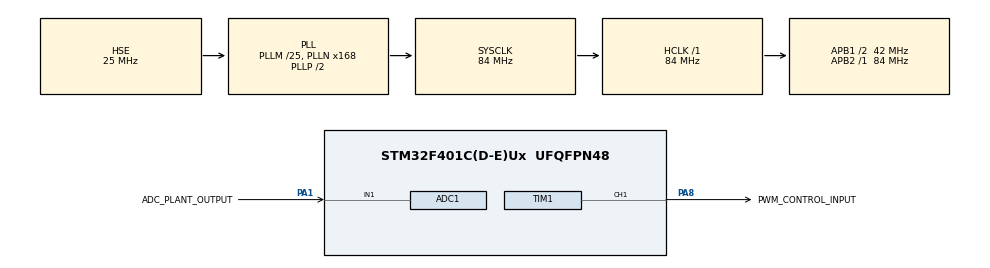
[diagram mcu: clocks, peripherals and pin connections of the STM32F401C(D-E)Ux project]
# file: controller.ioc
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ADC1.Channel-0\#ChannelRegularConversion=ADC_CHANNEL_1
ADC1.ClockPrescaler=ADC_CLOCK_SYNC_PCLK_DIV8
ADC1.ContinuousConvMode=ENABLE
ADC1.DMAContinuousRequests=ENABLE
ADC1.NbrOfConversionFlag=1
ADC1.Rank-0\#ChannelRegularConversion=1
ADC1.SamplingTime-0\#ChannelRegularConversion=ADC_SAMPLETIME_112CYCLES
ADC1.master=1
Dma.ADC1.0.Direction=DMA_PERIPH_TO_MEMORY
Dma.ADC1.0.FIFOMode=DMA_FIFOMODE_DISABLE
Dma.ADC1.0.Instance=DMA2_Stream0
Dma.ADC1.0.MemDataAlignment=DMA_MDATAALIGN_HALFWORD
Dma.ADC1.0.MemInc=DMA_MINC_ENABLE
Dma.ADC1.0.Mode=DMA_CIRCULAR
Dma.ADC1.0.PeriphDataAlignment=DMA_PDATAALIGN_HALFWORD
Dma.ADC1.0.PeriphInc=DMA_PINC_DISABLE
Dma.ADC1.0.Priority=DMA_PRIORITY_LOW
Dma.Request0=ADC1
Dma.Request1=TIM1_CH1
Dma.TIM1_CH1.1.Direction=DMA_PERIPH_TO_MEMORY
Dma.TIM1_CH1.1.FIFOMode=DMA_FIFOMODE_DISABLE
Dma.TIM1_CH1.1.Instance=DMA2_Stream1
Dma.TIM1_CH1.1.MemDataAlignment=DMA_MDATAALIGN_HALFWORD
Dma.TIM1_CH1.1.MemInc=DMA_MINC_ENABLE
Dma.TIM1_CH1.1.Mode=DMA_CIRCULAR
Dma.TIM1_CH1.1.PeriphDataAlignment=DMA_PDATAALIGN_HALFWORD
Dma.TIM1_CH1.1.PeriphInc=DMA_PINC_DISABLE
Dma.TIM1_CH1.1.Priority=DMA_PRIORITY_LOW
Mcu.Family=STM32F4
Mcu.Name=STM32F401C(D-E)Ux
Mcu.Package=UFQFPN48
Mcu.UserConstants=PWM_COUNTER_PERIOD,1000-1
NVIC.DMA2_Stream0_IRQn=true\:0\:0\:false\:false\:true\:false\:true\:true
NVIC.DMA2_Stream1_IRQn=true\:0\:0\:false\:false\:true\:false\:true\:true
NVIC.PriorityGroup=NVIC_PRIORITYGROUP_4
NVIC.TIM2_IRQn=true\:0\:0\:false\:false\:true\:true\:true\:true
PA1.GPIO_Label=ADC_PLANT_OUTPUT
PA1.Signal=ADCx_IN1
PA13.Mode=Serial_Wire
PA13.Signal=SYS_JTMS-SWDIO
PA14.Mode=Serial_Wire
PA14.Signal=SYS_JTCK-SWCLK
PA8.GPIO_Label=PWM_CONTROL_INPUT
PA8.Signal=S_TIM1_CH1
PH0\ -\ OSC_IN.Mode=HSE-External-Oscillator
PH0\ -\ OSC_IN.Signal=RCC_OSC_IN
PH1\ -\ OSC_OUT.Mode=HSE-External-Oscillator
PH1\ -\ OSC_OUT.Signal=RCC_OSC_OUT
ProjectManager.HeapSize=0x200
ProjectManager.StackSize=0x400
ProjectManager.TargetToolchain=STM32CubeIDE
RCC.48MHZClocksFreq_Value=42000000
RCC.AHBFreq_Value=84000000
RCC.APB1CLKDivider=RCC_HCLK_DIV2
RCC.APB1Freq_Value=42000000
RCC.APB1TimFreq_Value=84000000
RCC.APB2Freq_Value=84000000
RCC.APB2TimFreq_Value=84000000
RCC.CortexFreq_Value=84000000
RCC.HCLKFreq_Value=84000000
RCC.HSE_VALUE=25000000
RCC.HSI_VALUE=16000000
RCC.LSE_VALUE=32768
RCC.PLLM=25
RCC.PLLN=168
RCC.PLLSourceVirtual=RCC_PLLSOURCE_HSE
RCC.SYSCLKFreq_VALUE=84000000
RCC.SYSCLKSource=RCC_SYSCLKSOURCE_PLLCLK
RCC.VCOOutputFreq_Value=168000000
SH.ADCx_IN1.0=ADC1_IN1,IN1
SH.S_TIM1_CH1.0=TIM1_CH1,PWM Generation1 CH1
TIM1.Channel-PWM\ Generation1\ CH1=TIM_CHANNEL_1
TIM1.Period=PWM_COUNTER_PERIOD
TIM1.Prescaler=84-1
TIM2.Period=50000-1
TIM2.Prescaler=84-1
VP_TIM2_VS_ClockSourceINT.Mode=Internal
board=custom

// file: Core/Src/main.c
/* USER CODE BEGIN Header */
/**
  ******************************************************************************
  * @file           : main.c
  * @brief          : Main program body
  ******************************************************************************
  * @attention
  *
  * Copyright (c) 2025 STMicroelectronics.
  * All rights reserved.
  *
  * This software is licensed under terms that can be found in the LICENSE file
  * in the root directory of this software component.
  * If no LICENSE file comes with this software, it is provided AS-IS.
  *
  ******************************************************************************
  */
/* USER CODE END Header */
#include "main.h"

/* USER CODE BEGIN Includes */
#include "ControllerModel.h"
#include "ReferenceInputModel.h"
/* USER CODE END Includes */

/* USER CODE BEGIN PD */
#define VOLT_REF 3.33f
#define DATA12_TO_VOLT (VOLT_REF/0xfff)
#define VOLT_TO_PWM_DUTY ((PWM_COUNTER_PERIOD)/VOLT_REF)
/* USER CODE END PD */

ADC_HandleTypeDef hadc1;
DMA_HandleTypeDef hdma_adc1;

TIM_HandleTypeDef htim1;
TIM_HandleTypeDef htim2;
DMA_HandleTypeDef hdma_tim1_ch1;

/* USER CODE BEGIN PV */
uint16_t dma_adc_sensor_input = 0;
uint16_t dma_pwm_duty_out = 0;
uint16_t pwm_out_duty = 0;

float y = 0.f, r = 1.f, e = 0.f, u = 0.f;
/* USER CODE END PV */

void SystemClock_Config(void);
static void MX_GPIO_Init(void);
static void MX_DMA_Init(void);
static void MX_ADC1_Init(void);
static void MX_TIM1_Init(void);
static void MX_TIM2_Init(void);

int main(void)
{

  /* MCU Configuration--------------------------------------------------------*/

  /* Reset of all peripherals, Initializes the Flash interface and the Systick. */
  HAL_Init();

  /* Configure the system clock */
  SystemClock_Config();

  /* Initialize all configured peripherals */
  MX_GPIO_Init();
  MX_DMA_Init();
  MX_ADC1_Init();
  MX_TIM1_Init();
  MX_TIM2_Init();
  /* USER CODE BEGIN 2 */
  ControllerModel_initialize();
  ReferenceInputModel_initialize();
  HAL_TIM_PWM_Start_DMA(&htim1, TIM_CHANNEL_1, (uint32_t*) &dma_pwm_duty_out, (uint32_t) 1);
  HAL_ADC_Start_DMA(&hadc1, (uint32_t*) &dma_adc_sensor_input, (uint32_t) 1);
  HAL_TIM_Base_Start_IT(&htim2);
  /* USER CODE END 2 */

  /* Infinite loop */
  while (1)
  {

  }
}

void SystemClock_Config(void)
{
  RCC_OscInitTypeDef RCC_OscInitStruct = {0};
  RCC_ClkInitTypeDef RCC_ClkInitStruct = {0};

  /** Configure the main internal regulator output voltage
  */
  __HAL_RCC_PWR_CLK_ENABLE();
  __HAL_PWR_VOLTAGESCALING_CONFIG(PWR_REGULATOR_VOLTAGE_SCALE2);

  /** Initializes the RCC Oscillators according to the specified parameters
  * in the RCC_OscInitTypeDef structure.
  */
  RCC_OscInitStruct.OscillatorType = RCC_OSCILLATORTYPE_HSE;
  RCC_OscInitStruct.HSEState = RCC_HSE_ON;
  RCC_OscInitStruct.PLL.PLLState = RCC_PLL_ON;
  RCC_OscInitStruct.PLL.PLLSource = RCC_PLLSOURCE_HSE;
  RCC_OscInitStruct.PLL.PLLM = 25;
  RCC_OscInitStruct.PLL.PLLN = 168;
  RCC_OscInitStruct.PLL.PLLP = RCC_PLLP_DIV2;
  RCC_OscInitStruct.PLL.PLLQ = 4;
  if (HAL_RCC_OscConfig(&RCC_OscInitStruct) != HAL_OK)
  {
    Error_Handler();
  }

  /** Initializes the CPU, AHB and APB buses clocks
  */
  RCC_ClkInitStruct.ClockType = RCC_CLOCKTYPE_HCLK|RCC_CLOCKTYPE_SYSCLK
                              |RCC_CLOCKTYPE_PCLK1|RCC_CLOCKTYPE_PCLK2;
  RCC_ClkInitStruct.SYSCLKSource = RCC_SYSCLKSOURCE_PLLCLK;
  RCC_ClkInitStruct.AHBCLKDivider = RCC_SYSCLK_DIV1;
  RCC_ClkInitStruct.APB1CLKDivider = RCC_HCLK_DIV2;
  RCC_ClkInitStruct.APB2CLKDivider = RCC_HCLK_DIV1;

  if (HAL_RCC_ClockConfig(&RCC_ClkInitStruct, FLASH_LATENCY_2) != HAL_OK)
  {
    Error_Handler();
  }
}

static void MX_ADC1_Init(void)
{

  ADC_ChannelConfTypeDef sConfig = {0};

  /** Configure the global features of the ADC (Clock, Resolution, Data Alignment and number of conversion)
  */
  hadc1.Instance = ADC1;
  hadc1.Init.ClockPrescaler = ADC_CLOCK_SYNC_PCLK_DIV8;
  hadc1.Init.Resolution = ADC_RESOLUTION_12B;
  hadc1.Init.ScanConvMode = DISABLE;
  hadc1.Init.ContinuousConvMode = ENABLE;
  hadc1.Init.DiscontinuousConvMode = DISABLE;
  hadc1.Init.ExternalTrigConvEdge = ADC_EXTERNALTRIGCONVEDGE_NONE;
  hadc1.Init.ExternalTrigConv = ADC_SOFTWARE_START;
  hadc1.Init.DataAlign = ADC_DATAALIGN_RIGHT;
  hadc1.Init.NbrOfConversion = 1;
  hadc1.Init.DMAContinuousRequests = ENABLE;
  hadc1.Init.EOCSelection = ADC_EOC_SINGLE_CONV;
  if (HAL_ADC_Init(&hadc1) != HAL_OK)
  {
    Error_Handler();
  }

  /** Configure for the selected ADC regular channel its corresponding rank in the sequencer and its sample time.
  */
  sConfig.Channel = ADC_CHANNEL_1;
  sConfig.Rank = 1;
  sConfig.SamplingTime = ADC_SAMPLETIME_112CYCLES;
  if (HAL_ADC_ConfigChannel(&hadc1, &sConfig) != HAL_OK)
  {
    Error_Handler();
  }

}

static void MX_TIM1_Init(void)
{

  TIM_MasterConfigTypeDef sMasterConfig = {0};
  TIM_OC_InitTypeDef sConfigOC = {0};
  TIM_BreakDeadTimeConfigTypeDef sBreakDeadTimeConfig = {0};

  htim1.Instance = TIM1;
  htim1.Init.Prescaler = 84-1;
  htim1.Init.CounterMode = TIM_COUNTERMODE_UP;
  htim1.Init.Period = PWM_COUNTER_PERIOD;
  htim1.Init.ClockDivision = TIM_CLOCKDIVISION_DIV1;
  htim1.Init.RepetitionCounter = 0;
  htim1.Init.AutoReloadPreload = TIM_AUTORELOAD_PRELOAD_DISABLE;
  if (HAL_TIM_PWM_Init(&htim1) != HAL_OK)
  {
    Error_Handler();
  }
  sMasterConfig.MasterOutputTrigger = TIM_TRGO_RESET;
  sMasterConfig.MasterSlaveMode = TIM_MASTERSLAVEMODE_DISABLE;
  if (HAL_TIMEx_MasterConfigSynchronization(&htim1, &sMasterConfig) != HAL_OK)
  {
    Error_Handler();
  }
  sConfigOC.OCMode = TIM_OCMODE_PWM1;
  sConfigOC.Pulse = 0;
  sConfigOC.OCPolarity = TIM_OCPOLARITY_HIGH;
  sConfigOC.OCNPolarity = TIM_OCNPOLARITY_HIGH;
  sConfigOC.OCFastMode = TIM_OCFAST_DISABLE;
  sConfigOC.OCIdleState = TIM_OCIDLESTATE_RESET;
  sConfigOC.OCNIdleState = TIM_OCNIDLESTATE_RESET;
  if (HAL_TIM_PWM_ConfigChannel(&htim1, &sConfigOC, TIM_CHANNEL_1) != HAL_OK)
  {
    Error_Handler();
  }
  sBreakDeadTimeConfig.OffStateRunMode = TIM_OSSR_DISABLE;
  sBreakDeadTimeConfig.OffStateIDLEMode = TIM_OSSI_DISABLE;
  sBreakDeadTimeConfig.LockLevel = TIM_LOCKLEVEL_OFF;
  sBreakDeadTimeConfig.DeadTime = 0;
  sBreakDeadTimeConfig.BreakState = TIM_BREAK_DISABLE;
  sBreakDeadTimeConfig.BreakPolarity = TIM_BREAKPOLARITY_HIGH;
  sBreakDeadTimeConfig.AutomaticOutput = TIM_AUTOMATICOUTPUT_DISABLE;
  if (HAL_TIMEx_ConfigBreakDeadTime(&htim1, &sBreakDeadTimeConfig) != HAL_OK)
  {
    Error_Handler();
  }
  HAL_TIM_MspPostInit(&htim1);

}

static void MX_TIM2_Init(void)
{

  TIM_ClockConfigTypeDef sClockSourceConfig = {0};
  TIM_MasterConfigTypeDef sMasterConfig = {0};

  htim2.Instance = TIM2;
  htim2.Init.Prescaler = 84-1;
  htim2.Init.CounterMode = TIM_COUNTERMODE_UP;
  htim2.Init.Period = 50000-1;
  htim2.Init.ClockDivision = TIM_CLOCKDIVISION_DIV1;
  htim2.Init.AutoReloadPreload = TIM_AUTORELOAD_PRELOAD_DISABLE;
  if (HAL_TIM_Base_Init(&htim2) != HAL_OK)
  {
    Error_Handler();
  }
  sClockSourceConfig.ClockSource = TIM_CLOCKSOURCE_INTERNAL;
  if (HAL_TIM_ConfigClockSource(&htim2, &sClockSourceConfig) != HAL_OK)
  {
    Error_Handler();
  }
  sMasterConfig.MasterOutputTrigger = TIM_TRGO_RESET;
  sMasterConfig.MasterSlaveMode = TIM_MASTERSLAVEMODE_DISABLE;
  if (HAL_TIMEx_MasterConfigSynchronization(&htim2, &sMasterConfig) != HAL_OK)
  {
    Error_Handler();
  }

}

static void MX_DMA_Init(void)
{

  /* DMA controller clock enable */
  __HAL_RCC_DMA2_CLK_ENABLE();

  /* DMA interrupt init */
  /* DMA2_Stream0_IRQn interrupt configuration */
  HAL_NVIC_SetPriority(DMA2_Stream0_IRQn, 0, 0);
  HAL_NVIC_EnableIRQ(DMA2_Stream0_IRQn);
  /* DMA2_Stream1_IRQn interrupt configuration */
  HAL_NVIC_SetPriority(DMA2_Stream1_IRQn, 0, 0);
  HAL_NVIC_EnableIRQ(DMA2_Stream1_IRQn);

}

static void MX_GPIO_Init(void)
{

  /* GPIO Ports Clock Enable */
  __HAL_RCC_GPIOH_CLK_ENABLE();
  __HAL_RCC_GPIOA_CLK_ENABLE();

}

/* USER CODE BEGIN 4 */
void HAL_TIM_PeriodElapsedCallback(TIM_HandleTypeDef *htim) {
	if (htim->Instance == htim2.Instance) {
		y = DATA12_TO_VOLT*dma_adc_sensor_input;

		ReferenceInputModel_step();
		r = ReferenceInputModel_Y.r;
		e = r - y;
		ControllerModel_U.e = e;
		ControllerModel_step();
		u = ControllerModel_Y.u;

		dma_pwm_duty_out = VOLT_TO_PWM_DUTY*u;
	}
}
/* USER CODE END 4 */

void Error_Handler(void)
{
  __disable_irq();
  while (1)
  {
  }
}
